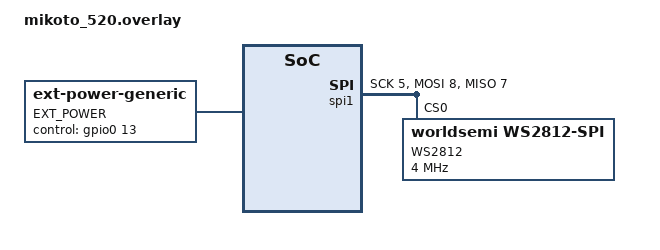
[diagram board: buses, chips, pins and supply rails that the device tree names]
#include <dt-bindings/led/led.h>

&spi1 {
	compatible = "nordic,nrf-spim";
	status = "okay";
	mosi-pin = <8>; //pin 0.08
	// Unused pins, needed for SPI definition, but not used by the ws2812 driver itself.
	sck-pin = <5>;
	miso-pin = <7>;

	led_strip: ws2812@0 {
		compatible = "worldsemi,ws2812-spi";
		label = "WS2812";

		/* SPI */
		reg = <0>; /* ignored, but necessary for SPI bindings */
		spi-max-frequency = <4000000>;

		/* WS2812 */
		chain-length = <11>; /* number of LEDs */
		spi-one-frame = <0x70>;
		spi-zero-frame = <0x40>;
		color-mapping = <LED_COLOR_ID_GREEN LED_COLOR_ID_RED LED_COLOR_ID_BLUE>;
  	};
};

/ {

	ext-power {
		compatible = "zmk,ext-power-generic";
		label = "EXT_POWER";
		control-gpios = <&gpio0 13 GPIO_ACTIVE_HIGH>;
		init-delay-ms = <50>;
	};

    chosen {
        zmk,underglow = &led_strip;
    };
};

